# R40 register map
Vendor: Allwinner; Series: R40; File version: 0.1
CPU: CA7 0, little endian, MPU, FPU, double-precision FPU, 0 interrupt priority bits
Registers are 32-bit, read-write, reset 0x0 unless marked. A register's access mark holds for its fields unless they carry their own. Offsets are from the block's base; [hi:lo] are bit positions; lines under a group give offsets from that group; {n}, {i} and the like mark numbered series; 'fields as' and 'values as' point back to an identical list.

## EMAC
Base 0x01C0B000
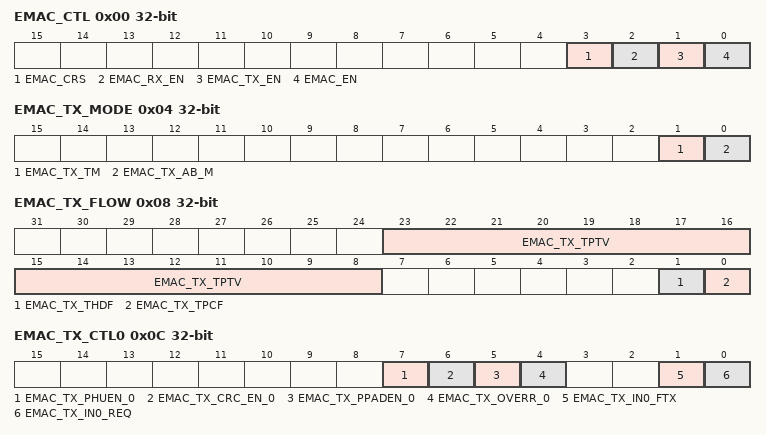
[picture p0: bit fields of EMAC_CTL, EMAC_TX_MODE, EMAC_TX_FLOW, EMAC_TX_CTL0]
0x00 EMAC_CTL — EMAC Control Register
  [3] EMAC_CRS ro — EMAC Carrier Sense 0: Idle 1: Carrier lost
    0=Idle; 1=Carrier lost
  [2] EMAC_RX_EN — EMAC RX Enable 0: Disable 1: Enable
    0=Disable; 1=Enable
  [1] EMAC_TX_EN — EMAC TX Enable 0: Disable 1: Enable
    0=Disable; 1=Enable
  [0] EMAC_EN — EMAC Enable Control 0: Disable 1: Enable
    0=Disable; 1=Enable
0x04 EMAC_TX_MODE
  [1] EMAC_TX_TM — Transmit Mode Select 0: CPU mode 1: DMA mode
    0=CPU_mode; 1=DMA_mode
  [0] EMAC_TX_AB_M — EMAC TX Aborted Packet Mode 0: Aborted frame auto clear 1: Aborted frame wait
    0=Aborted frame auto clear; 1=Aborted_frame_wait
0x08 EMAC_TX_FLOW — EMAC TX Flow Control Register
  [23:8] EMAC_TX_TPTV — EMAC TX Transmit PAUSE Timer Value
  [1] EMAC_TX_THDF — EMAC TX Transmit Half-Duplex Flow Control 0: Disable 1: Enable
    0=Disable; 1=Enable
  [0] EMAC_TX_TPCF — EMAC TX Transmit PAUSE Control Frame Note: Write `1` to active pause control operation, auto clears after pause transmission completion.
0x0C EMAC_TX_CTL0 — EMAC TX Control Register0
  [7] EMAC_TX_PHUEN_0 — EMAC TX Per-Packet Huge Enable 0: Disable 1: Enable Setting the bit to `1` will allow the transmission of a Huge Frame (over 1518 bytes) without truncating the current transmit frame.
    0=Disable; 1=Enable Setting the bit to `1` will allow the transmission of a Huge Frame (over 1518 bytes) without truncating the current transmit frame
  [6] EMAC_TX_CRC_EN_0 — EMAC TX Per-Packet CRC Enable 0: Disable 1: Enable Setting the bit to `1` will append a correct CRC Value to the frame
    0=Disable; 1=Enable Setting the bit to `1` will append a correct CRC Value to the frame
  [5] EMAC_TX_PPADEN_0 — EMAC TX Per-Packet Pad Enable 0: Disable 1: Enable Setting the bit to `1` will pad the current transmit frame to the IEEE minimum of 64 bytes and append a correct CRC Value to the frame
    0=Disable; 1=Enable Setting the bit to `1` will pad the current transmit frame to the IEEE minimum of 64 bytes and append a correct CRC Value to the frame
  [4] EMAC_TX_OVERR_0 — EMAC TX Per-Packet Over Ride Enable 0: Disable 1: Enable When this bit is set to `1`, the per-packet settings in this Register will override the current configuration settings In EMAC MAC Registers.
    0=Disable; 1=Enable When this bit is set to `1`, the per-packet settings in this Register will override the current configuration settings In EMAC MAC Registers
  [1] EMAC_TX_IN0_FTX — EMAC TX Flush TX FIFO Index0 0: Disable 1: Enable Write `1` to Flush TX FIFO index0
    0=Disable; 1=Enable Write `1` to Flush TX FIFO index0
  [0] EMAC_TX_IN0_REQ — EMAC TX Index0 Transmit Request 0: Idle 1: Active Note: Auto clears after sending completely.
    0=Idle; 1=Active Note: Auto clears after sending completely
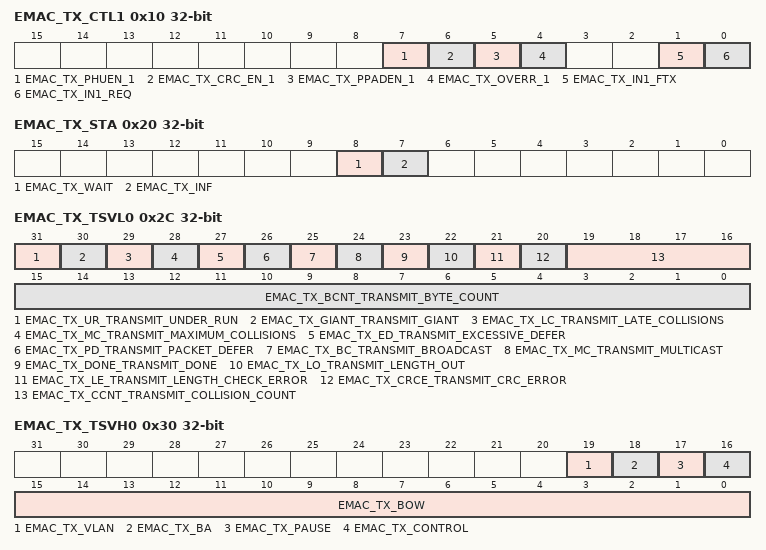
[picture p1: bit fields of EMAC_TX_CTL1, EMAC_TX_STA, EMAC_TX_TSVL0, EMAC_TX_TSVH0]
0x10 EMAC_TX_CTL1 — EMAC TX Control Register1
  [7] EMAC_TX_PHUEN_1 — EMAC TX Per-Packet Huge Enable 0: Disable 1: Enable Setting the bit to `1` will allow the transmission of a Huge Frame (over 1518 bytes) without truncating the current transmit frame.
    values as EMAC_TX_CTL0.EMAC_TX_PHUEN_0
  [6] EMAC_TX_CRC_EN_1 — EMAC TX Per-Packet CRC Enable 0: Disable 1: Enable Setting the bit to `1` will append a correct CRC Value to the frame
    values as EMAC_TX_CTL0.EMAC_TX_CRC_EN_0
  [5] EMAC_TX_PPADEN_1 — EMAC TX Per-Packet Pad Enable 0: Disable 1: Enable Setting the bit to `1` will pad the current transmit frame to the IEEE minimum of 64 bytes and append a correct CRC Value to the frame
    values as EMAC_TX_CTL0.EMAC_TX_PPADEN_0
  [4] EMAC_TX_OVERR_1 — EMAC TX Per-Packet Over Ride Enable 0: Disable 1: Enable When this bit is set to `1`, the per-packet settings in this Register will override the current configuration settings In EMAC MAC Registers.
    values as EMAC_TX_CTL0.EMAC_TX_OVERR_0
  [1] EMAC_TX_IN1_FTX — EMAC TX Flush TX FIFO Index1 0: Disable 1: Enable Write `1` to Flush TX FIFO index1
    0=Disable; 1=Enable Write `1` to Flush TX FIFO index1
  [0] EMAC_TX_IN1_REQ — EMAC TX Index1 Transmit Request 0: Idle 1: Active Note: Auto clears after sending completely
    0=Idle; 1=Active Note: Auto clears after sending completely
0x14 EMAC_TX_INS — EMAC TX Index Select Register
  [0] EMAC_TX_INS — EMAC TX Index Select 0: TX RAM0 1: TX RAM1
    0=TX_RAM0; 1=TX_RAM1
0x18 EMAC_TX_PL0 — EMAC TX Packet Length Register
  [11:0] EMAC_TX_PA_LENTH_0 — EMAC TX Packet Length for Index0
0x1C EMAC_TX_PL1 — EMAC TX Packet Length Register
  [11:0] EMAC_TX_PA_LENTH_1 — EMAC TX Packet Length for Index1
0x20 EMAC_TX_STA — EMAC TX Status Register
  [8] EMAC_TX_WAIT — EMAC TX Waiting 0: Normal 1: TX is Waiting Note: Only active Aborted Frame Waiting Mode, Write `1` to clear this bit and wake up TX
    0=Normal; 1=TX (TX is Waiting Note: Only active Aborted Frame Waiting Mode, Write `1` to clear this bit and wake up TX)
  [7] EMAC_TX_INF ro — EMAC TX Index Flag 0: Index0 is active 1: Index1 is active
    0=Index0 is active; 1=Index1 is active
0x24 EMAC_TX_IO_DATA0 — EMAC TX IO Data Register0
  [31:0] EMAC_TX_IO_DATA wo — Write data into internal RAM
0x28 EMAC_TX_IO_DATA1 reset not defined — EMAC TX IO Data Register1
0x2C EMAC_TX_TSVL0 — EMAC TX TSV Low Word Register0
  [31] EMAC_TX_UR_TRANSMIT_UNDER_RUN ro
  [30] EMAC_TX_GIANT_TRANSMIT_GIANT ro
  [29] EMAC_TX_LC_TRANSMIT_LATE_COLLISIONS ro
  [28] EMAC_TX_MC_TRANSMIT_MAXIMUM_COLLISIONS ro
  [27] EMAC_TX_ED_TRANSMIT_EXCESSIVE_DEFER ro
  [26] EMAC_TX_PD_TRANSMIT_PACKET_DEFER ro
  [25] EMAC_TX_BC_TRANSMIT_BROADCAST ro
  [24] EMAC_TX_MC_TRANSMIT_MULTICAST ro
  [23] EMAC_TX_DONE_TRANSMIT_DONE ro
  [22] EMAC_TX_LO_TRANSMIT_LENGTH_OUT ro — EMAC_TX_LO Transmit Length Out of Range
  [21] EMAC_TX_LE_TRANSMIT_LENGTH_CHECK_ERROR ro
  [20] EMAC_TX_CRCE_TRANSMIT_CRC_ERROR ro
  [19:16] EMAC_TX_CCNT_TRANSMIT_COLLISION_COUNT ro
  [15:0] EMAC_TX_BCNT_TRANSMIT_BYTE_COUNT ro
0x30 EMAC_TX_TSVH0 — EMAC TX TSV High Word Register0
  [19] EMAC_TX_VLAN ro — Transmit VLAN Tagged frame
  [18] EMAC_TX_BA ro — Backpressure Applied
  [17] EMAC_TX_PAUSE ro — Transmit Pause Control Frame
  [16] EMAC_TX_CONTROL ro — Transmit Control Frame
  [15:0] EMAC_TX_BOW ro — Total Bytes Transmitted on Wire
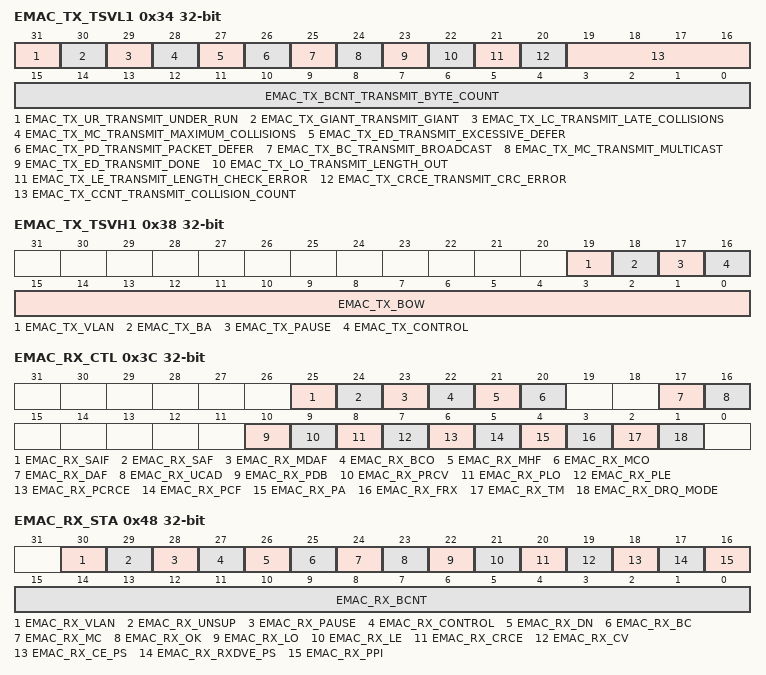
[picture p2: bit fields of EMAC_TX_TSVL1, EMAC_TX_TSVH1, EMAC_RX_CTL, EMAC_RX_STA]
0x34 EMAC_TX_TSVL1 — EMAC TX TSV Low Word Register1
  [31] EMAC_TX_UR_TRANSMIT_UNDER_RUN ro
  [30] EMAC_TX_GIANT_TRANSMIT_GIANT ro
  [29] EMAC_TX_LC_TRANSMIT_LATE_COLLISIONS ro
  [28] EMAC_TX_MC_TRANSMIT_MAXIMUM_COLLISIONS ro
  [27] EMAC_TX_ED_TRANSMIT_EXCESSIVE_DEFER ro
  [26] EMAC_TX_PD_TRANSMIT_PACKET_DEFER ro
  [25] EMAC_TX_BC_TRANSMIT_BROADCAST ro
  [24] EMAC_TX_MC_TRANSMIT_MULTICAST ro
  [23] EMAC_TX_ED_TRANSMIT_DONE ro
  [22] EMAC_TX_LO_TRANSMIT_LENGTH_OUT ro — EMAC_TX_LO Transmit Length Out of Range
  [21] EMAC_TX_LE_TRANSMIT_LENGTH_CHECK_ERROR ro
  [20] EMAC_TX_CRCE_TRANSMIT_CRC_ERROR ro
  [19:16] EMAC_TX_CCNT_TRANSMIT_COLLISION_COUNT ro
  [15:0] EMAC_TX_BCNT_TRANSMIT_BYTE_COUNT ro
0x38 EMAC_TX_TSVH1 — EMAC TX TSV High Word Register1
  [19] EMAC_TX_VLAN ro — Transmit VLAN Tagged Frame
  [18] EMAC_TX_BA ro — Backpressure Applied
  [17] EMAC_TX_PAUSE ro — Transmit Pause Control Frame
  [16] EMAC_TX_CONTROL ro — Transmit Control Frame
  [15:0] EMAC_TX_BOW ro — Total Bytes Transmitted on Wire
0x3C EMAC_RX_CTL — EMAC RX Control Register
  [25] EMAC_RX_SAIF — EMC RX SA Inverse Filtering 0: Disable 1: Enable Note: Active when EMAC_RX_SAF enable
    0=Disable; 1=Enable Note: Active when EMAC_RX_SAF enable
  [24] EMAC_RX_SAF — EMAC RX SA Filtering Enable 0: Disable 1: Enable
    0=Disable; 1=Enable
  [23] EMAC_RX_MDAF — EMAC RX Multicast DA Filtering Enable 0: Disable 1: Eanble
    0=Disable; 1=Eanble
  [22] EMAC_RX_BCO — EMAC RX Broadcast Packet Accept 0: not accept 1: Accept Note: Active when EMAC_RX_DAF enable
    0=not_accept; 1=Accept Note: Active when EMAC_RX_DAF enable
  [21] EMAC_RX_MHF — EMAC RX Multicast Hash Filtering Enable 0: Disable 1: Enable Note: Active when EMAC_RX_MCO enable
    0=Disable; 1=Enable Note: Active when EMAC_RX_MCO enable
  [20] EMAC_RX_MCO — EMAC RX Multicast Packet Accept 0: not accept 1: Accept
    0=not_accept; 1=Accept
  [17] EMAC_RX_DAF — EMC RX DA Filtering Enable 0: Disable 1: Enable Note: Active when EMAC_RX_UCAD is set
    0=Disable; 1=Enable Note: Active when EMAC_RX_UCAD is set
  [16] EMAC_RX_UCAD — EMAC RX Unicast Packet Accept 0: not accept 1: Accept
    0=not_accept; 1=Accept
  [10] EMAC_RX_PDB — EMAC RX Pass packet with Dribble Nibble 0: Disable 1: Enable
    0=Disable; 1=Enable
  [9] EMAC_RX_PRCV — EMAC RX Pass Packet with Receive Code Violation 0: Disable 1: Enable
    0=Disable; 1=Enable
  [8] EMAC_RX_PLO — EMAC RX Pass Packet with Length Out of Range 0: Disable 1: Enable
    0=Disable; 1=Enable
  [7] EMAC_RX_PLE — EMAC RX Pass Packet with Length Errors 0: Disable 1: Enable
    0=Disable; 1=Enable
  [6] EMAC_RX_PCRCE — EMAC RX Pass Packet with CRC Errors 0: Disable 1: Enable
    0=Disable; 1=Enable
  [5] EMAC_RX_PCF — EMAC RX Pass Control Frame 0: Disable 1: Enable
    0=Disable; 1=Enable
  [4] EMAC_RX_PA — EMAC RX Pass All Enable 0: Disable 1: Enable Note: if this bit is set, all packets will be transmitted to the upper layer regardless of other settings.
    0=Disable; 1=Enable Note: if this bit is set, all packets will be transmitted to the upper layer regardless of other settings
  [3] EMAC_RX_FRX — EMAC RX FIFO Flush Write `1` to Flush RX FIFO
  [2] EMAC_RX_TM — EMAC_RX Transmit Mode 0: CPU 1: DMA Note: This bit is only valid in single frame mode
    0=CPU; 1=DMA (DMA Note: This bit is only valid in single frame mode)
  [1] EMAC_RX_DRQ_MODE — EMAC RX DRQ Mode 0: DRQ always asserted 1: DRQ asserted automatically Note: Only valid in DMA Mode.
    0=DRQ_always_asserted; 1=DRQ asserted automatically Note: Only valid in DMA Mode
0x40 EMAC_RX_HASH0 — EMAC RX Hash Table Register0
  [31:0] EMAC_RX_HASH_L — EMAC RX HASH Table Low 32bit Note: The 64-bit Hash table is used for group address filtering. For hash filtering, the contents of the destination address in the incoming frame is passed through the CRC logic, and the upper 6 bits of the CRC register are used to index the contents of the Hash table. The most significant bit determines the register to be used (Hash Table 0/Hash Table 1), and the other 5 bits determine which bit within the register. A hash value of 5b'00000 selects bit 0 of the selected register, and a value of 5b'11111 selects bit 31 of the selected register.
0x44 EMAC_RX_HASH1 — EMAC RX Hash Table Register1
  [31:0] EMAC_RX_HASH_H — EMAC RX HASH Table High 32bit Note: The 64-bit Hash table is used for group address filtering. For hash filtering, the contents of the destination address in the incoming frame is passed through the CRC logic, and the upper 6 bits of the CRC register are used to index the contents of the Hash table. The most significant bit determines the register to be used (Hash Table 0/Hash Table 1), and the other 5 bits determine which bit within the register. A hash value of 5b'00000 selects bit 0 of the selected register, and a value of 5b'11111 selects bit 31 of the selected register.
0x48 EMAC_RX_STA — EMAC RX Status Register
  [30] EMAC_RX_VLAN ro — Receive VLAN TYPE Detected
  [29] EMAC_RX_UNSUP ro — Receive Unsupported Op-code
  [28] EMAC_RX_PAUSE ro — Receive Pause Control Frame
  [27] EMAC_RX_CONTROL ro — Receive Control Frame
  [26] EMAC_RX_DN ro — Dribble Nibble
  [25] EMAC_RX_BC ro — Broadcast Packet
  [24] EMAC_RX_MC ro — Multicast Packet
  [23] EMAC_RX_OK ro — Receive OK
  [22] EMAC_RX_LO ro — Length Out of Range
  [21] EMAC_RX_LE ro — Length Check Error
  [20] EMAC_RX_CRCE ro — CRC Error
  [19] EMAC_RX_CV ro — Receive Code Violation
  [18] EMAC_RX_CE_PS ro — Carrier Event Previously Seen
  [17] EMAC_RX_RXDVE_PS ro — RXDV Event Previously Seen
  [16] EMAC_RX_PPI ro — Packet Previously Ignored
  [15:0] EMAC_RX_BCNT ro — Received Byte Count
0x4C EMAC_RX_IO_DATA
  [31:0] EMAC_RX_IO_DATA ro — Read data from internal ram
0x50 EMAC_RX_FBC — EMAC RX FIFO Byte Counter
  [14:0] EMAC_RX_FIFO_BC ro
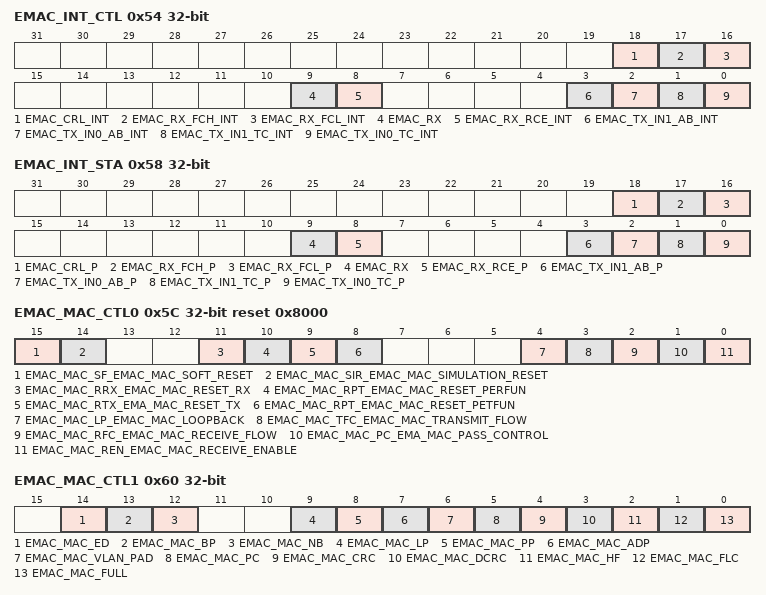
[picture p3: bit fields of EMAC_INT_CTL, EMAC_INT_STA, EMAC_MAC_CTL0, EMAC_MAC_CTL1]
0x54 EMAC_INT_CTL — EMAC Interrupt Control Register
  [18] EMAC_CRL_INT — EMAC Carrier Loss Interrupt 0: Disable 1: Enable
    0=Disable; 1=Enable
  [17] EMAC_RX_FCH_INT — EMAC RX Flow Control High Level Interrupt 0: Disable 1: Enable Note: If Enable, when free space less than 3K, the Interrupt will active
    0=Disable; 1=Enable Note: If Enable, when free space less than 3K, the Interrupt will active
  [16] EMAC_RX_FCL_INT — EMAC RX Flow Control Low Level Interrupt 0: Disable 1: Enable Note: If Enable, when free space less than 8K, the Interrupt will active
    0=Disable; 1=Enable Note: If Enable, when free space less than 8K, the Interrupt will active
  [9] EMAC_RX — _OR_INT EMAC RX Overrun Interrupt Enable 0: Disable 1: Enable
    0=Disable; 1=Enable
  [8] EMAC_RX_RCE_INT — EMAC RX Received Interrupt Enable 0: Disable 1: Enable
    0=Disable; 1=Enable
  [3] EMAC_TX_IN1_AB_INT — EMAC TX FIFO Index1 Aborted Interrupt Enable 0: Disable 1: Enable
    0=Disable; 1=Enable
  [2] EMAC_TX_IN0_AB_INT — EMAC TX FIFO Index0 Aborted Interrupt Enable 0: Disable 1: Enable
    0=Disable; 1=Enable
  [1] EMAC_TX_IN1_TC_INT — EMAC TX FIFO Index1 Transmit Completed Interrupt Enable 0: Disable 1: Enable
    0=Disable; 1=Enable
  [0] EMAC_TX_IN0_TC_INT — EMAC TX FIFO Index0 Transmit Completed Interrupt Enable 0: Disable 1: Enable
    0=Disable; 1=Enable
0x58 EMAC_INT_STA — EMAC Interrupt Status Register
  [all] fields
    0=No_Pending; 1=Pending Note: Write `1` to clear
  [18] EMAC_CRL_P — EMAC Carrier Loss Interrupt Pending 0: No Pending 1: Pending Note: Write `1` to clear
  [17] EMAC_RX_FCH_P — EMAC RX Flow Control High Level Interrupt Pending 0: No Pending 1: Pending Note: Write `1` to clear
  [16] EMAC_RX_FCL_P — EMAC RX Flow Control Low Level Interrupt Pending 0: No Pending 1: Pending Note: Write `1` to clear
  [9] EMAC_RX — _OR_P EMAC RX Overrun Interrupt Pending 0: No Pending 1: Pending Note: Write `1` to clear
  [8] EMAC_RX_RCE_P — EMAC RX Received Interrupt Pending 0: No Pending 1: Pending Note: Write `1` to clear
  [3] EMAC_TX_IN1_AB_P — EMAC TX FIFO Index1 Aborted Interrupt Pending 0: No Pending 1: Pending Note: Write `1` to clear
  [2] EMAC_TX_IN0_AB_P — EMAC TX FIFO Index0 Aborted Interrupt Pending 0: No Pending 1: Pending Note: Write `1` to clear
  [1] EMAC_TX_IN1_TC_P — EMAC TX FIFO Index1 Transmit Completed Interrupt Pending 0: No Pending 1: Pending Note: Write `1` to clear
  [0] EMAC_TX_IN0_TC_P — EMAC TX FIFO Index0 Transmit Completed Interrupt Pending 0: No Pending 1: Pending Note: Write `1` to clear
0x5C EMAC_MAC_CTL0 reset 0x8000 — EMAC MAC Control Register0
  [15] EMAC_MAC_SF_EMAC_MAC_SOFT_RESET — EMAC_MAC_SF EMAC MAC Soft Reset 0: Disable 1: Enable
    0=Disable; 1=Enable
  [14] EMAC_MAC_SIR_EMAC_MAC_SIMULATION_RESET — EMAC_MAC_SIR EMAC MAC Simulation Reset 0: Disable 1: Enable
    0=Disable; 1=Enable
  [11] EMAC_MAC_RRX_EMAC_MAC_RESET_RX — EMAC_MAC_RRX EMAC MAC Reset RX Logic 0: Disable 1: Enable
    0=Disable; 1=Enable
  [10] EMAC_MAC_RPT_EMAC_MAC_RESET_PERFUN — EMAC_MAC_RPT EMAC MAC Reset PERFUN 0: Disable 1: Enable
    0=Disable; 1=Enable
  [9] EMAC_MAC_RTX_EMA_MAC_RESET_TX — EMAC_MAC_RTX EMA MAC Reset TX logic 0: Disable 1: Enable
    0=Disable; 1=Enable
  [8] EMAC_MAC_RPT_EMAC_MAC_RESET_PETFUN — EMAC_MAC_RPT EMAC MAC Reset PETFUN 0: Disable 1: Enable
    0=Disable; 1=Enable
  [4] EMAC_MAC_LP_EMAC_MAC_LOOPBACK — EMAC_MAC_LP EMAC MAC LOOPBACK 0: Disable 1: Enable
    0=Disable; 1=Enable
  [3] EMAC_MAC_TFC_EMAC_MAC_TRANSMIT_FLOW — EMAC_MAC_TFC EMAC MAC Transmit Flow Control 0: Disable 1: Enable When enabled, PAUSE Flow Control frames are allowed to be transmitted
    0=Disable; 1=Enable When enabled, PAUSE Flow Control frames are allowed to be transmitted
  [2] EMAC_MAC_RFC_EMAC_MAC_RECEIVE_FLOW — EMAC_MAC_RFC EMAC MAC Receive Flow Control 0: Disable 1: Enable When enabled, the MAC acts upon received PAUSE Flow Control frames
    0=Disable; 1=Enable When enabled, the MAC acts upon received PAUSE Flow Control frames
  [1] EMAC_MAC_PC_EMA_MAC_PASS_CONTROL — EMAC_MAC_PC EMA MAC Pass Control frames 0: Disable 1: Enable
    0=Disable; 1=Enable
  [0] EMAC_MAC_REN_EMAC_MAC_RECEIVE_ENABLE — EMAC_MAC_REN EMAC MAC Receive Enable 0: Disable 1: Enable
    0=Disable; 1=Enable
0x60 EMAC_MAC_CTL1 — EMAC MAC Control Register1
  [14] EMAC_MAC_ED — EMAC MAC Excess Defer 0: Disable 1: Enable
    0=Disable; 1=Enable
  [13] EMAC_MAC_BP — EMAC MAC Backpressure/no back off 0: Disable 1: Enable
    0=Disable; 1=Enable
  [12] EMAC_MAC_NB — EMAC MAC No Back off 0: Disable 1: Enable
    0=Disable; 1=Enable
  [9] EMAC_MAC_LP — EMAC MAC Long Preamble Enforcement Enable 0: Disable 1: Enable
    0=Disable; 1=Enable
  [8] EMAC_MAC_PP — EMAC MAC Pure Preamble Enforcement Enable 0: Disable 1: Enable
    0=Disable; 1=Enable
  [7] EMAC_MAC_ADP — EMAC MAC Auto Detect Pad Enable 0: Disable 1: Enable
    0=Disable; 1=Enable
  [6] EMAC_MAC_VLAN_PAD — EMAC MAC VLAN PAD Enable 0: Disable 1: Enable
    0=Disable; 1=Enable
  [5] EMAC_MAC_PC — EMAC MAC PAD/CRC Enable 0: Disable 1: Enable
    0=Disable; 1=Enable
  [4] EMAC_MAC_CRC — EMAC MAC CRC Enable 0: Disable 1: Enable
    0=Disable; 1=Enable
  [3] EMAC_MAC_DCRC — EMAC MAC Delayed CRC 0: Disable 1: Enable
    0=Disable; 1=Enable
  [2] EMAC_MAC_HF — EMAC MAC Huge Frame Enable 0: Disable 1: Enable
    0=Disable; 1=Enable
  [1] EMAC_MAC_FLC — EMAC MAC Frame Length Checking 0: Disable 1: Enable
    0=Disable; 1=Enable
  [0] EMAC_MAC_FULL — EMAC MAC Full duplex 0: Half duplex 1: Full duplex
    0=Half duplex; 1=Full duplex
0x64 EMAC_MAC_IPGT — EMAC MAC BTB Inter-Packet-Gap Register
  [6:0] EMAC_MAC_IPGT — EMAC MAC Back to Back Inter Packet Gap
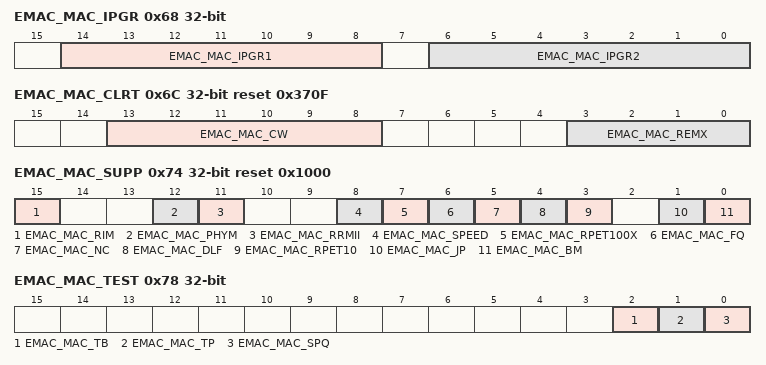
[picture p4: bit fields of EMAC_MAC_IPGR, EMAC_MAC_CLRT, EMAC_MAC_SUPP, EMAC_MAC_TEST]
0x68 EMAC_MAC_IPGR — EMAC MAC NBTB Inter-Packet-Gap Register
  [14:8] EMAC_MAC_IPGR1 — EMAC MAC Non Back to Back Inter Packet Gap Part1
  [6:0] EMAC_MAC_IPGR2 — EMAC MAC Non Back to Back Inter Packet Gap Part2
0x6C EMAC_MAC_CLRT reset 0x370F — EMAC MAC Collision/ Retry Limit Register
  [13:8] EMAC_MAC_CW — EMAC MAC Collision Window
  [3:0] EMAC_MAC_REMX — EMAC MAC Retransmission Maximum
0x70 EMAC_MAC_MAXF reset 0x600 — EMAC MAC Maximum Frame Register
  [15:0] EMAC_MAC_MAXF — EMAC MAC Maximum Frame Length
0x74 EMAC_MAC_SUPP reset 0x1000 — EMAC MAC PHY Support Register
  [15] EMAC_MAC_RIM — EMAC MAC Reset Interface Module 0: Disable 1: Enable
    0=Disable; 1=Enable
  [12] EMAC_MAC_PHYM — EMAC MAC PHY Mode 0: SMII MAC 1: SMII PHY
    0=SMII_MAC; 1=SMII_PHY
  [11] EMAC_MAC_RRMII — EMAC MAC Reset RMII 0: Disable 1: Enable
    0=Disable; 1=Enable
  [8] EMAC_MAC_SPEED — EMAC MAC Speed 0: 10M 1: 100M
    0=_10M; 1=_100M
  [7] EMAC_MAC_RPET100X — EMAC MAC Reset PET100X 0: Disable 1: Enable
    0=Disable; 1=Enable
  [6] EMAC_MAC_FQ — EMAC MAC Force Quiet 0: Disable 1: Enable
    0=Disable; 1=Enable
  [5] EMAC_MAC_NC — EMAC MAC No Cipher 0: Disable 1: Enable
    0=Disable; 1=Enable
  [4] EMAC_MAC_DLF — EMAC MAC Disable Link Fail 0: Disable 1: Enable
    0=Disable; 1=Enable
  [3] EMAC_MAC_RPET10 — EMAC MAC Reset PET10 0: Disable 1: Enable
    0=Disable; 1=Enable
  [1] EMAC_MAC_JP — EMAC MAC Jabber Protection Enable 0: Disable 1: Enable
    0=Disable; 1=Enable
  [0] EMAC_MAC_BM — EMAC MAC Bit Mode 0: nibble clock 1: bit clock
    0=nibble clock; 1=bit (bit clock)
0x78 EMAC_MAC_TEST
  [2] EMAC_MAC_TB — EMAC MAC Test backpressure
  [1] EMAC_MAC_TP — EMAC MAC Test Pause
  [0] EMAC_MAC_SPQ — EMAC MAC Shortcut Pause Quanta
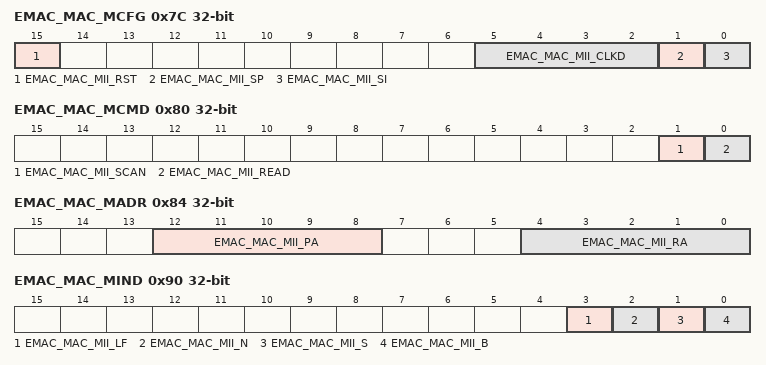
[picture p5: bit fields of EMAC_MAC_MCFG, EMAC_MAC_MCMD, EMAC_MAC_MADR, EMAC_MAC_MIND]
0x7C EMAC_MAC_MCFG — EMAC MAC MII Mgmt Configuration Register
  [15] EMAC_MAC_MII_RST — EMAC MAC MII Reset 0: Disable 1: Enable
    0=Disable; 1=Enable
  [5:2] EMAC_MAC_MII_CLKD — EMAC MAC MII Clock Divider 0000: 4 0001: 4 0010: 6 0011: 8 0100: 10 0101: 14 0110: 20 0111: 28 1000: 32 1001: 40 1010: 48 1011: 56 1100: 64 1101: 72 1110: 80 1111: 88
  [1] EMAC_MAC_MII_SP — EMAC MAC MII Suppress Preamble
  [0] EMAC_MAC_MII_SI — EMAC MAC MII Scan Increment
0x80 EMAC_MAC_MCMD — EMAC MAC MII Mgmt Command Register
  [1] EMAC_MAC_MII_SCAN
  [0] EMAC_MAC_MII_READ — EMAC MAC MII Read This bit causes the MII interface to perform a single read cycle. The read data is returned in register EMAC_MAC_MRDD.
0x84 EMAC_MAC_MADR — EMAC MAC MII Mgmt Address Register
  [12:8] EMAC_MAC_MII_PA — EMAC MAC MII PHY Address
  [4:0] EMAC_MAC_MII_RA — EMAC MAC MII Register Address
0x88 EMAC_MAC_MWTD — EMAC MAC MII Mgmt Write Data Register
  [15:0] EMAC_MAC_MII_WD wo — EMAC MAC MII Write Data When written, a MII interface write cycle is performed using 16-bit data and the pre-configured PHY and Register address in EMAC_MAC_MADR.
0x8C EMAC_MAC_MRDD — EMAC MAC MII Mgmt Read Data Register
  [15:0] EMAC_MAC_MII_RD ro — EMAC MAC MII Read Data
0x90 EMAC_MAC_MIND — EMAC MAC MII Mgmt Indicators Register
  [3] EMAC_MAC_MII_LF ro — EMAC MAC MII Link Fail
  [2] EMAC_MAC_MII_N ro — EMAC MAC MII Not Valid
  [1] EMAC_MAC_MII_S ro — EMAC MAC MII Scanning
  [0] EMAC_MAC_MII_B ro — EMAC MAC MII Busy
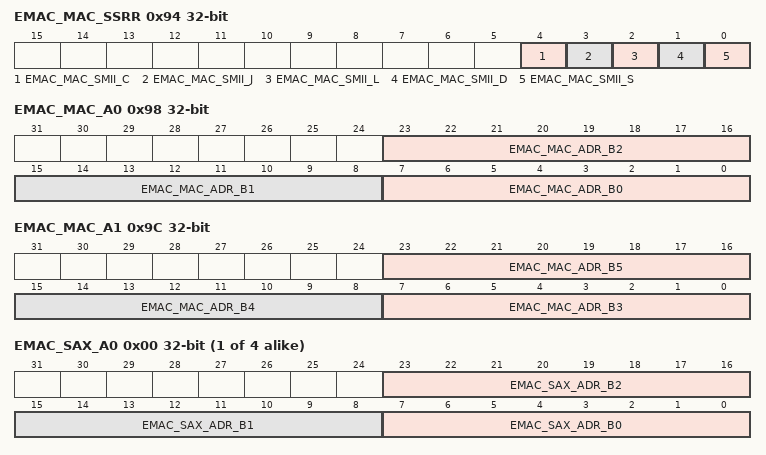
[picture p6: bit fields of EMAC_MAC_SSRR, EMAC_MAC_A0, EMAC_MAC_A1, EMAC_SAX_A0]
0x94 EMAC_MAC_SSRR — EMAC MAC SMII Status Register
  [4] EMAC_MAC_SMII_C ro — EMAC MAC SMII Clash
  [3] EMAC_MAC_SMII_J ro — EMAC MAC SMII Jabber
  [2] EMAC_MAC_SMII_L ro — EMAC MAC SMII Link 0: fail 1: ok
    0=fail; 1=ok
  [1] EMAC_MAC_SMII_D ro — EMAC MAC SMII Duplex 0: Half Duplex 1: Full Duplex
    0=Half Duplex; 1=Full Duplex
  [0] EMAC_MAC_SMII_S ro — EMAC MAC SMII Speed 0: 10M 1: 100M
    0=_10M; 1=_100M
0x98 EMAC_MAC_A0 — EMAC MAC Address Register0
  [23:16] EMAC_MAC_ADR_B2 wo — EMAC MAC Address Byte2
  [15:8] EMAC_MAC_ADR_B1 wo — EMAC MAC Address Byte1
  [7:0] EMAC_MAC_ADR_B0 wo — EMAC MAC Address Byte0
0x9C EMAC_MAC_A1 — EMAC MAC Address Register1
  [23:16] EMAC_MAC_ADR_B5 wo — EMAC MAC Address Byte5
  [15:8] EMAC_MAC_ADR_B4 wo — EMAC MAC Address Byte4
  [7:0] EMAC_MAC_ADR_B3 wo — EMAC MAC Address Byte3
{0xA0+8i} _N[{i}] (i=0..3) group
  0x00 EMAC_SAX_A0
    [23:16] EMAC_SAX_ADR_B2 wo — EMAC SA Filtering Address Byte2
    [15:8] EMAC_SAX_ADR_B1 wo — EMAC SA Filtering Address Byte1
    [7:0] EMAC_SAX_ADR_B0 wo — EMAC SA Filtering Address Byte0
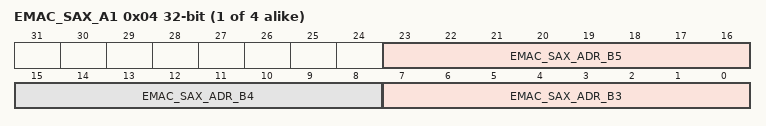
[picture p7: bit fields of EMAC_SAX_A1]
  0x04 EMAC_SAX_A1
    [23:16] EMAC_SAX_ADR_B5 wo — EMAC SA Filtering Address Byte5
    [15:8] EMAC_SAX_ADR_B4 wo — EMAC SA Filtering Address Byte4
    [7:0] EMAC_SAX_ADR_B3 wo — EMAC SA Filtering Address Byte3
{0xC0+4i} EMAC_MDAFX_A0[{i}] (i=0..7) — EMAC_MDAFX_A0[{i}]
  [23:16] EMAC_MDA_B2 — EMAC Multicast DA filtering Address Byte2
  [16:8] EMAC_MDA_B1 — EMAC Multicast DA filtering Address Byte1
  [7:0] EMAC_MDA_B0 — EMAC Multicast DA filtering Address Byte0
0xE0 EMAC_MDAFX_A1
  [23:16] EMAC_MDA_B5 — EMAC Multicast DA filtering Address Byte5
  [16:8] EMAC_MDA_B4 — EMAC Multicast DA filtering Address Byte4
  [7:0] EMAC_MDA_B3 — EMAC Multicast DA filtering Address Byte3
